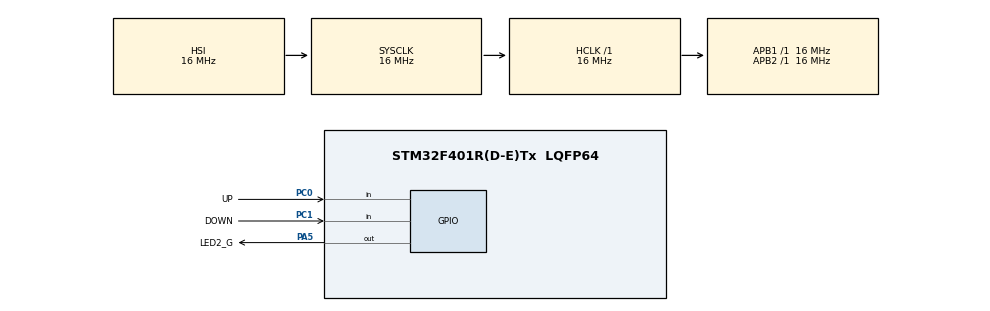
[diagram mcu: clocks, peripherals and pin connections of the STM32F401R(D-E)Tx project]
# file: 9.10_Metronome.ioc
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Mcu.Family=STM32F4
RCC.CortexFreq_Value=16000000
PC0.GPIO_Label=UP
PC0.Signal=GPIO_Input
ProjectManager.StackSize=0x400
PA13.Signal=SYS_JTMS-SWDIO
TIM1.Prescaler=999
ProjectManager.TargetToolchain=STM32CubeIDE
RCC.LSE_VALUE=32768
RCC.AHBFreq_Value=16000000
PA5.Signal=GPIO_Output
RCC.HSE_VALUE=25000000
board=custom
PC1.GPIO_PuPd=GPIO_PULLUP
RCC.VCOOutputFreq_Value=192000000
RCC.APB2Freq_Value=16000000
PA14.Mode=Serial_Wire
PC1.GPIO_Label=DOWN
PA13.Mode=Serial_Wire
Mcu.Name=STM32F401R(D-E)Tx
VP_TIM1_VS_ClockSourceINT.Mode=Internal
RCC.SYSCLKFreq_VALUE=16000000
Mcu.Package=LQFP64
PA5.GPIO_Label=LED2_G
PA14.Signal=SYS_JTCK-SWCLK
ProjectManager.HeapSize=0x200
NVIC.TIM1_UP_TIM10_IRQn=true\:0\:0\:false\:false\:true\:true\:true
RCC.HSI_VALUE=16000000
NVIC.PriorityGroup=NVIC_PRIORITYGROUP_4
TIM1.Period=7999
PC0.GPIO_PuPd=GPIO_PULLUP
RCC.APB1Freq_Value=16000000
PC1.Signal=GPIO_Input

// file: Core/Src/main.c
/* USER CODE BEGIN Header */
/**
  ******************************************************************************
  * @file           : main.c
  * @brief          : Main program body
  ******************************************************************************
  * @attention
  *
  * <h2><center>&copy; Copyright (c) 2021 STMicroelectronics.
  * All rights reserved.</center></h2>
  *
  * This software component is licensed by ST under BSD 3-Clause license,
  * the "License"; You may not use this file except in compliance with the
  * License. You may obtain a copy of the License at:
  *                        opensource.org/licenses/BSD-3-Clause
  *
  ******************************************************************************
  */
/* USER CODE END Header */
#include "main.h"
#include "tim.h"
#include "gpio.h"

/* USER CODE BEGIN Includes */
	void UP_DOWN__BPM(uint8_t bpm);
/* USER CODE END Includes */

/* USER CODE BEGIN PV */

	//Function interrupt handler to toggle the led
	void HAL_TIM_PeriodElapsedCallback(TIM_HandleTypeDef *htim)
	{
		HAL_GPIO_TogglePin(LED2_G_GPIO_Port, LED2_G_Pin);
	}

/* USER CODE END PV */

void SystemClock_Config(void);

int main(void)
{

  /* MCU Configuration--------------------------------------------------------*/

  /* Reset of all peripherals, Initializes the Flash interface and the Systick. */
  HAL_Init();

  /* Configure the system clock */
  SystemClock_Config();

  /* Initialize all configured peripherals */
  MX_GPIO_Init();
  MX_TIM1_Init();
  /* USER CODE BEGIN 2 */

  //start timer 1
  //the code starts with 60 Beats per minute by default
  HAL_TIM_Base_Start_IT(&htim1);

  //BPM saves the number of beats per minute (0 - 255 BPM)
  uint8_t BPM = 60;

  /* USER CODE END 2 */

  /* Infinite loop */
  while (1)
  {

	  //conditional to check if the UP button was pressed (mode pull-up)
	  if(HAL_GPIO_ReadPin(UP_GPIO_Port, UP_Pin) ==  GPIO_PIN_RESET)
	  {
		  // increment BMP
		  BPM++;
		  //function to change the Auto-reload register value
		  UP_DOWN__BPM(BPM);

		  //debounce while
		  while(1)
		  {
			  if(HAL_GPIO_ReadPin(UP_GPIO_Port, UP_Pin) ==  GPIO_PIN_SET)
			  {
				  break;
			  }
		  }
	  }
	  if(HAL_GPIO_ReadPin(DOWN_GPIO_Port, DOWN_Pin) ==  GPIO_PIN_RESET)
	  	  {
	  		  // increment BMP
	  		  BPM--;
	  		  //function to change the Auto-reload register value
	  		  UP_DOWN__BPM(BPM);

	  		//debounce while
	  		while(1)
	  			{
	  				 if(HAL_GPIO_ReadPin(DOWN_GPIO_Port, DOWN_Pin) ==  GPIO_PIN_SET)
	  				 {
	  						  break;
	  				 }
	  			 }
	  	  }

  }
}

void SystemClock_Config(void)
{
  RCC_OscInitTypeDef RCC_OscInitStruct = {0};
  RCC_ClkInitTypeDef RCC_ClkInitStruct = {0};

  /** Configure the main internal regulator output voltage
  */
  __HAL_RCC_PWR_CLK_ENABLE();
  __HAL_PWR_VOLTAGESCALING_CONFIG(PWR_REGULATOR_VOLTAGE_SCALE2);
  /** Initializes the RCC Oscillators according to the specified parameters
  * in the RCC_OscInitTypeDef structure.
  */
  RCC_OscInitStruct.OscillatorType = RCC_OSCILLATORTYPE_HSI;
  RCC_OscInitStruct.HSIState = RCC_HSI_ON;
  RCC_OscInitStruct.HSICalibrationValue = RCC_HSICALIBRATION_DEFAULT;
  RCC_OscInitStruct.PLL.PLLState = RCC_PLL_NONE;
  if (HAL_RCC_OscConfig(&RCC_OscInitStruct) != HAL_OK)
  {
    Error_Handler();
  }
  /** Initializes the CPU, AHB and APB buses clocks
  */
  RCC_ClkInitStruct.ClockType = RCC_CLOCKTYPE_HCLK|RCC_CLOCKTYPE_SYSCLK
                              |RCC_CLOCKTYPE_PCLK1|RCC_CLOCKTYPE_PCLK2;
  RCC_ClkInitStruct.SYSCLKSource = RCC_SYSCLKSOURCE_HSI;
  RCC_ClkInitStruct.AHBCLKDivider = RCC_SYSCLK_DIV1;
  RCC_ClkInitStruct.APB1CLKDivider = RCC_HCLK_DIV1;
  RCC_ClkInitStruct.APB2CLKDivider = RCC_HCLK_DIV1;

  if (HAL_RCC_ClockConfig(&RCC_ClkInitStruct, FLASH_LATENCY_0) != HAL_OK)
  {
    Error_Handler();
  }
}

/* USER CODE BEGIN 4 */

//function to increment and decrease the BPM. This is made by changing the Auto-reload register value
void UP_DOWN__BPM(uint8_t bpm)
{
	/*note: Bx= bpm
	 * 		TIoL= time which the interruption should occur and toggle the led
	 *
	 * we have the numbers of beats (Bx) in 60 seconds  =  Bx -> 60 s, then
	 * we need to know the period which the led should turn on or the period of one beat (PoB(s))= 60s/Bx, so
	 * in that period should occur two thing turn on the led and turn off the led, This means that the update

	 *  we need it  as a number because the Auto-reload register of timer 1 ask a number,
	 *  then we know that   1 second --> 16 x 10^3(also this is the number on Hz after the counter Prescaler),
	 *  (TIoL(16 x 10^3))-1 = ARvalue ---> ((60*16000)/(2*Bx))-1
	 */

	uint32_t ARvalue=((60.0*16000)/(2*bpm))-1;

	__HAL_TIM_SET_AUTORELOAD(&htim1,ARvalue);

	return;

}

/* USER CODE END 4 */

void Error_Handler(void)
{
  __disable_irq();
  while (1)
  {
  }
}

/************************ (C) COPYRIGHT STMicroelectronics *****END OF FILE****/
